# ATSAM3S2C device description
Architecture: CORTEX-M3; Family: SAM3; Series: SAM3S
Registers are 32-bit, read-write, no defined reset value unless marked. A register's access mark holds for its fields unless they carry their own. Offsets are from the block's base; [hi:lo] are bit positions.

## PDC — Peripheral DMA Controller
0x00 PERIPH_RPR — Receive Pointer Register
  [31:0] RXPTR
0x04 PERIPH_RCR — Receive Counter Register
  [15:0] RXCTR
0x08 PERIPH_TPR — Transmit Pointer Register
  [31:0] TXPTR — Transmit Counter Register
0x0C PERIPH_TCR — Transmit Counter Register
  [15:0] TXCTR
0x10 PERIPH_RNPR — Receive Next Pointer Register
  [31:0] RXNPTR — Receive Next Pointer
0x14 PERIPH_RNCR — Receive Next Counter Register
  [15:0] RXNCTR — Receive Next Counter
0x18 PERIPH_TNPR — Transmit Next Pointer Register
  [31:0] TXNPTR — Transmit Next Pointer
0x1C PERIPH_TNCR — Transmit Next Counter Register
  [15:0] TXNCTR — Transmit Counter Next
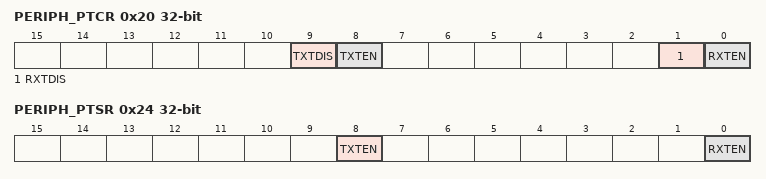
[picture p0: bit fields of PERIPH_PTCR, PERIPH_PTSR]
0x20 PERIPH_PTCR wo — Transfer Control Register
  [9] TXTDIS — Transmitter Transfer Disable
  [8] TXTEN — Transmitter Transfer Enable
  [1] RXTDIS — Receiver Transfer Disable
  [0] RXTEN — Receiver Transfer Enable
0x24 PERIPH_PTSR ro — Transfer Status Register
  [8] TXTEN — Transmitter Transfer Enable
  [0] RXTEN — Receiver Transfer Enable

## RSTC — Reset Controller
Instances: RSTC 0x400E1400
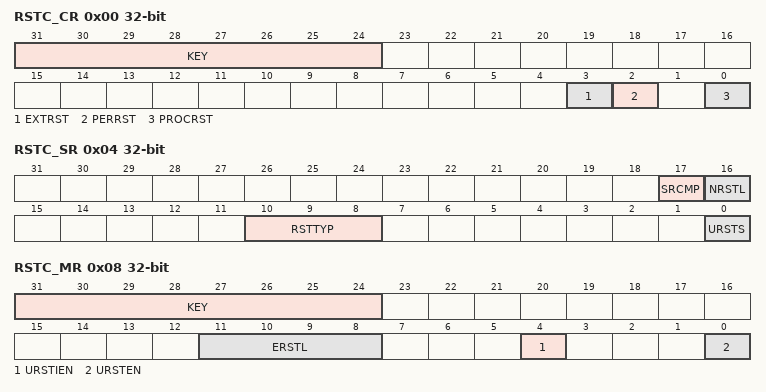
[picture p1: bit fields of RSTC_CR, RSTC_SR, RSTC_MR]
0x00 RSTC_CR wo — Control Register
  [31:24] KEY — System Reset Key
  [3] EXTRST — External Reset
  [2] PERRST — Peripheral Reset
  [0] PROCRST — Processor Reset
0x04 RSTC_SR ro — Status Register
  [17] SRCMP — Software Reset Command in Progress
  [16] NRSTL — NRST Pin Level
  [10:8] RSTTYP — Reset Type
  [0] URSTS — User Reset Status
0x08 RSTC_MR — Mode Register
  [31:24] KEY — Password
  [11:8] ERSTL — External Reset Length
  [4] URSTIEN — User Reset Interrupt Enable
  [0] URSTEN — User Reset Enable

## RTC — Real-time Clock
Instances: RTC 0x400E1460
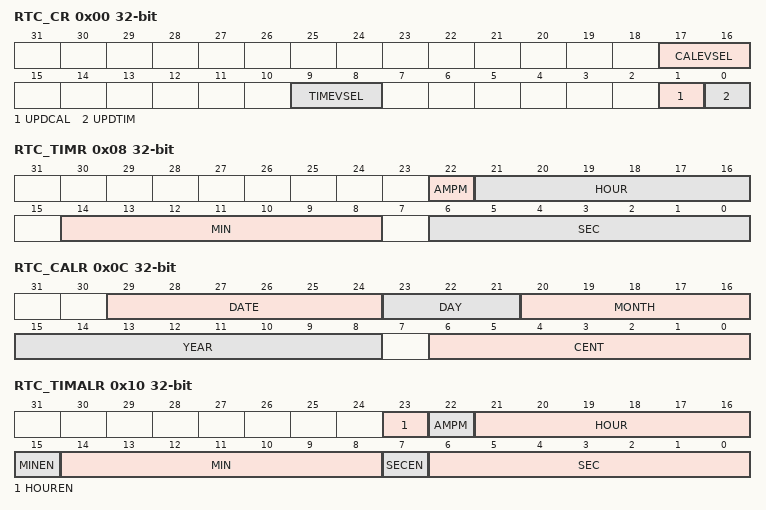
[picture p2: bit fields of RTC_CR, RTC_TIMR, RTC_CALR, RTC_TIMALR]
0x00 RTC_CR — Control Register
  [17:16] CALEVSEL — Calendar Event Selection
    0=WEEK (Week change (every Monday at time 00:00:00)); 1=MONTH (Month change (every 01 of each month at time 00:00:00)); 2=YEAR (Year change (every January 1 at time 00:00:00))
  [9:8] TIMEVSEL — Time Event Selection
    0=MINUTE (Minute change); 1=HOUR (Hour change); 2=MIDNIGHT (Every day at midnight); 3=NOON (Every day at noon)
  [1] UPDCAL — Update Request Calendar Register
  [0] UPDTIM — Update Request Time Register
0x04 RTC_MR — Mode Register
  [0] HRMOD — 12-/24-hour Mode
0x08 RTC_TIMR — Time Register
  [22] AMPM — Ante Meridiem Post Meridiem Indicator
  [21:16] HOUR — Current Hour
  [14:8] MIN — Current Minute
  [6:0] SEC — Current Second
0x0C RTC_CALR — Calendar Register
  [29:24] DATE — Current Day in Current Month
  [23:21] DAY — Current Day in Current Week
  [20:16] MONTH — Current Month
  [15:8] YEAR — Current Year
  [6:0] CENT — Current Century
0x10 RTC_TIMALR — Time Alarm Register
  [23] HOUREN — Hour Alarm Enable
  [22] AMPM — AM/PM Indicator
  [21:16] HOUR — Hour Alarm
  [15] MINEN — Minute Alarm Enable
  [14:8] MIN — Minute Alarm
  [7] SECEN — Second Alarm Enable
  [6:0] SEC — Second Alarm
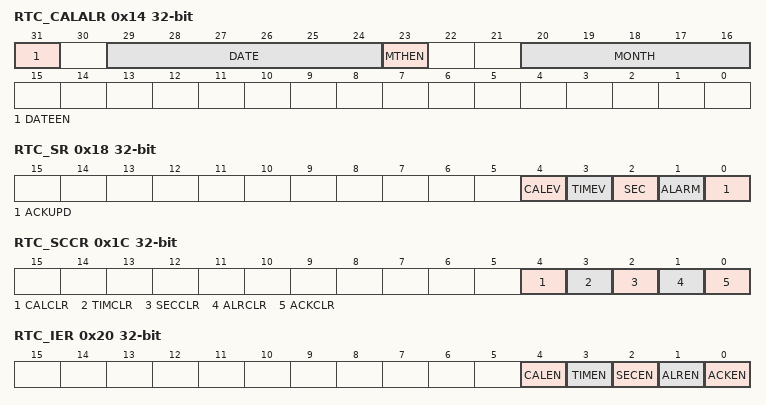
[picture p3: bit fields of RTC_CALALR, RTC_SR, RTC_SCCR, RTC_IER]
0x14 RTC_CALALR — Calendar Alarm Register
  [31] DATEEN — Date Alarm Enable
  [29:24] DATE — Date Alarm
  [23] MTHEN — Month Alarm Enable
  [20:16] MONTH — Month Alarm
0x18 RTC_SR ro — Status Register
  [4] CALEV — Calendar Event
    0=NO_CALEVENT (No calendar event has occurred since the last clear.); 1=CALEVENT (At least one calendar event has occurred since the last clear.)
  [3] TIMEV — Time Event
    0=NO_TIMEVENT (No time event has occurred since the last clear.); 1=TIMEVENT (At least one time event has occurred since the last clear.)
  [2] SEC — Second Event
    0=NO_SECEVENT (No second event has occurred since the last clear.); 1=SECEVENT (At least one second event has occurred since the last clear.)
  [1] ALARM — Alarm Flag
    0=NO_ALARMEVENT (No alarm matching condition occurred.); 1=ALARMEVENT (An alarm matching condition has occurred.)
  [0] ACKUPD — Acknowledge for Update
    0=FREERUN (Time and calendar registers cannot be updated.); 1=UPDATE (Time and calendar registers can be updated.)
0x1C RTC_SCCR wo — Status Clear Command Register
  [4] CALCLR — Calendar Clear
  [3] TIMCLR — Time Clear
  [2] SECCLR — Second Clear
  [1] ALRCLR — Alarm Clear
  [0] ACKCLR — Acknowledge Clear
0x20 RTC_IER wo — Interrupt Enable Register
  [4] CALEN — Calendar Event Interrupt Enable
  [3] TIMEN — Time Event Interrupt Enable
  [2] SECEN — Second Event Interrupt Enable
  [1] ALREN — Alarm Interrupt Enable
  [0] ACKEN — Acknowledge Update Interrupt Enable
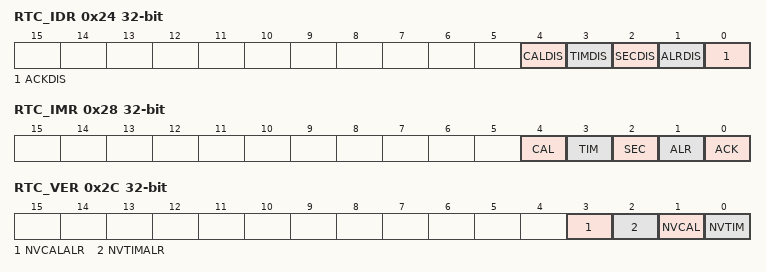
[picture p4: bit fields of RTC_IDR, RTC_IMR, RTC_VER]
0x24 RTC_IDR wo — Interrupt Disable Register
  [4] CALDIS — Calendar Event Interrupt Disable
  [3] TIMDIS — Time Event Interrupt Disable
  [2] SECDIS — Second Event Interrupt Disable
  [1] ALRDIS — Alarm Interrupt Disable
  [0] ACKDIS — Acknowledge Update Interrupt Disable
0x28 RTC_IMR ro — Interrupt Mask Register
  [4] CAL — Calendar Event Interrupt Mask
  [3] TIM — Time Event Interrupt Mask
  [2] SEC — Second Event Interrupt Mask
  [1] ALR — Alarm Interrupt Mask
  [0] ACK — Acknowledge Update Interrupt Mask
0x2C RTC_VER ro — Valid Entry Register
  [3] NVCALALR — Non-valid Calendar Alarm
  [2] NVTIMALR — Non-valid Time Alarm
  [1] NVCAL — Non-valid Calendar
  [0] NVTIM — Non-valid Time

## Notices in the file
SAM Software Package License
Copyright (c) %copyright_year%, Atmel Corporation
All rights reserved.
Redistribution and use in source and binary forms, with or without
modification, are permitted provided that the following condition is met:
- Redistributions of source code must retain the above copyright notice,
this list of conditions and the disclaimer below.
Atmel's name may not be used to endorse or promote products derived from
this software without specific prior written permission.
DISCLAIMER:  THIS SOFTWARE IS PROVIDED BY ATMEL "AS IS" AND ANY EXPRESS OR
IMPLIED WARRANTIES, INCLUDING, BUT NOT LIMITED TO, THE IMPLIED WARRANTIES OF
MERCHANTABILITY, FITNESS FOR A PARTICULAR PURPOSE AND NON-INFRINGEMENT ARE
DISCLAIMED. IN NO EVENT SHALL ATMEL BE LIABLE FOR ANY DIRECT, INDIRECT,
INCIDENTAL, SPECIAL, EXEMPLARY, OR CONSEQUENTIAL DAMAGES (INCLUDING, BUT NOT
LIMITED TO, PROCUREMENT OF SUBSTITUTE GOODS OR SERVICES; LOSS OF USE, DATA,
OR PROFITS; OR BUSINESS INTERRUPTION) HOWEVER CAUSED AND ON ANY THEORY OF
LIABILITY, WHETHER IN CONTRACT, STRICT LIABILITY, OR TORT (INCLUDING
NEGLIGENCE OR OTHERWISE) ARISING IN ANY WAY OUT OF THE USE OF THIS SOFTWARE,
EVEN IF ADVISED OF THE POSSIBILITY OF SUCH DAMAGE.
